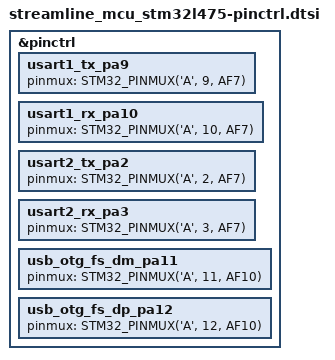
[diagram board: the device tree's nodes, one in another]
#include <zephyr/dt-bindings/pinctrl/stm32-pinctrl.h>

&pinctrl {
	/* USART1 */
	usart1_tx_pa9: usart1_tx_pa9 {
		pinmux = <STM32_PINMUX('A', 9, AF7)>;
	};
	usart1_rx_pa10: usart1_rx_pa10 {
		pinmux = <STM32_PINMUX('A', 10, AF7)>;
	};

	/* USART2 */
	usart2_tx_pa2: usart2_tx_pa2 {
		pinmux = <STM32_PINMUX('A', 2, AF7)>;
	};
	usart2_rx_pa3: usart2_rx_pa3 {
		pinmux = <STM32_PINMUX('A', 3, AF7)>;
	};

	/* USB OTG FS */
	usb_otg_fs_dm_pa11: usb_otg_fs_dm_pa11 {
		pinmux = <STM32_PINMUX('A', 11, AF10)>;
	};
	usb_otg_fs_dp_pa12: usb_otg_fs_dp_pa12 {
		pinmux = <STM32_PINMUX('A', 12, AF10)>;
	};
};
